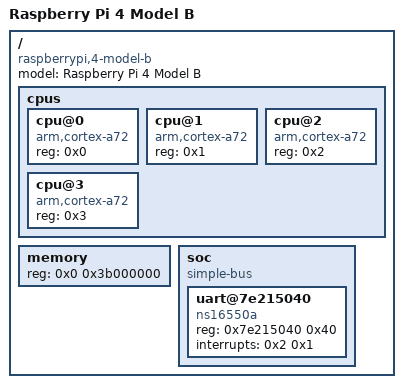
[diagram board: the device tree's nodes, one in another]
/dts-v1/;

/ {
    model = "Raspberry Pi 4 Model B";
    compatible = "raspberrypi,4-model-b", "brcm,bcm2711";

    cpus {
        cpu@0 {
            device_type = "cpu";
            compatible = "arm,cortex-a72";
            reg = <0x0>;
        };
        cpu@1 {
            device_type = "cpu";
            compatible = "arm,cortex-a72";
            reg = <0x1>;
        };
        cpu@2 {
            device_type = "cpu";
            compatible = "arm,cortex-a72";
            reg = <0x2>;
        };
        cpu@3 {
            device_type = "cpu";
            compatible = "arm,cortex-a72";
            reg = <0x3>;
        };
    };

    memory {
        device_type = "memory";
        reg = <0x0 0x3b000000>;
    };

    soc {
        compatible = "simple-bus";
        #address-cells = <1>;
        #size-cells = <1>;
        ranges;

        uart@7e215040 {
            compatible = "ns16550a";
            reg = <0x7e215040 0x40>;
            interrupts = <0x2 0x1>;
        };
    };
};
